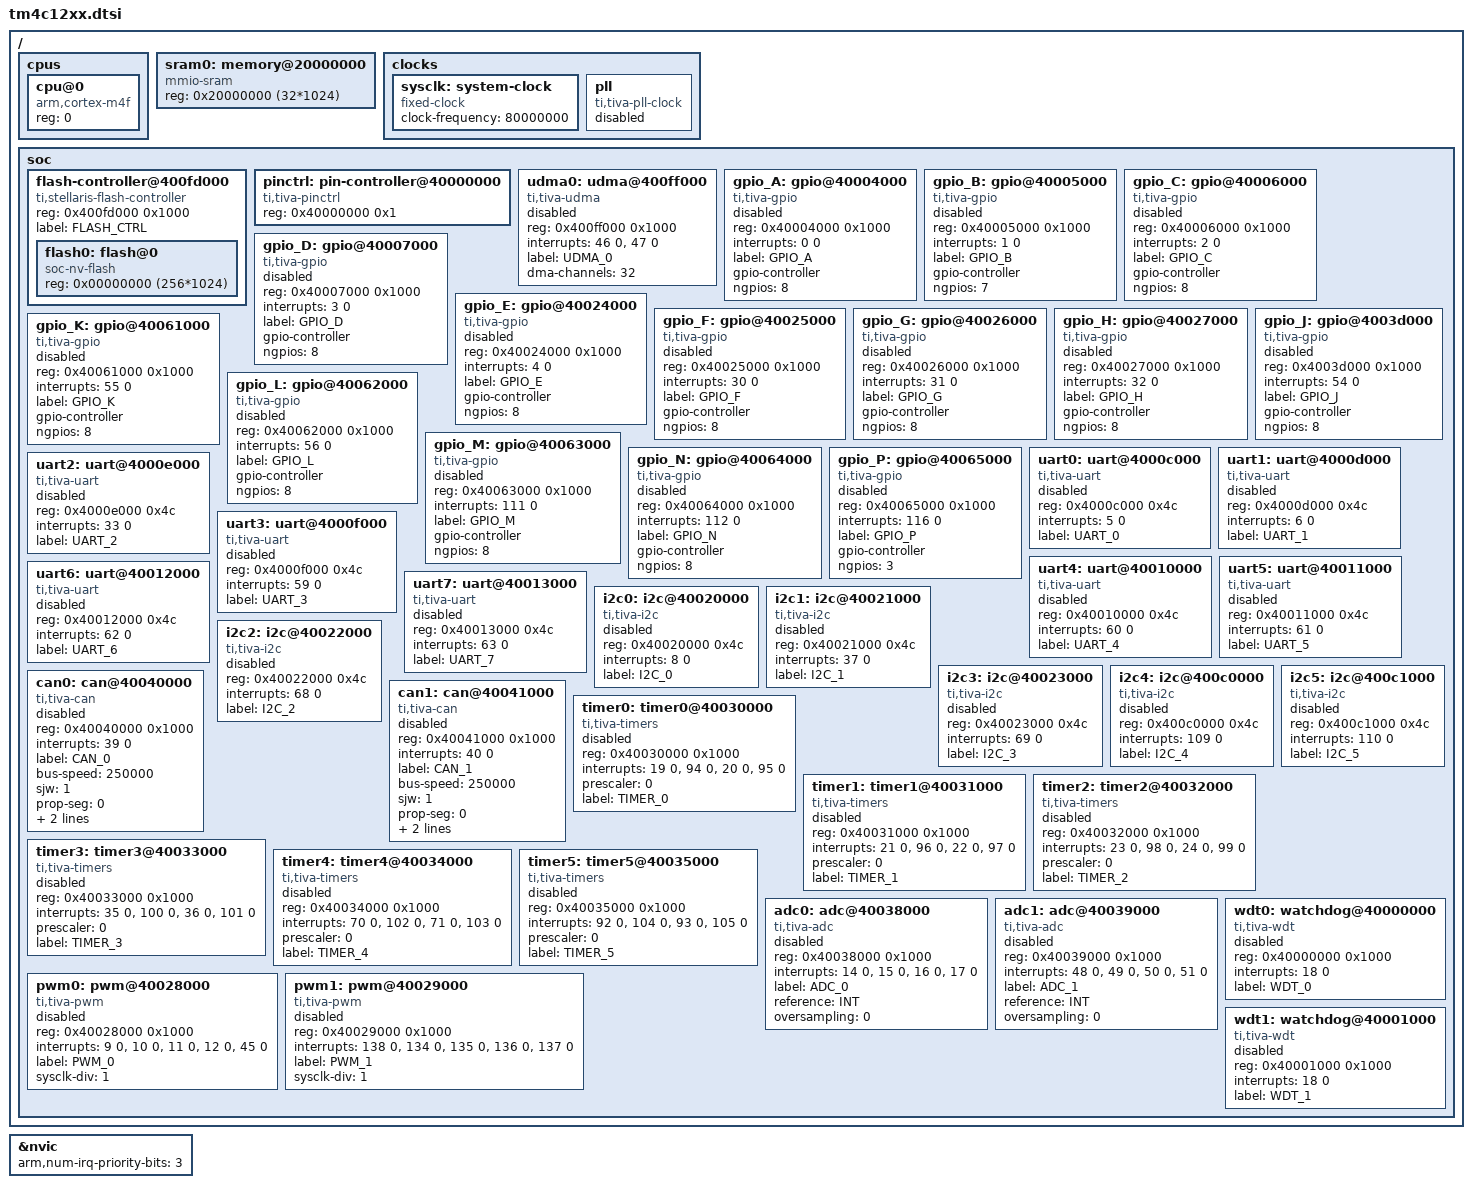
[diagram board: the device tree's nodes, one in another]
/*
 * Copyright (c) 2021 TIER SE
 *
 * SPDX-License-Identifier: Apache-2.0
 */

#include <arm/armv7-m.dtsi>
#include <dt-bindings/i2c/i2c.h>
#include <dt-bindings/gpio/gpio.h>

/ {
	cpus {
		#address-cells = <1>;
		#size-cells = <0>;

		cpu@0 {
			device_type = "cpu";
			compatible = "arm,cortex-m4f";
			reg = <0>;
		};
	};

	sram0: memory@20000000 {
		compatible = "mmio-sram";
		reg = <0x20000000 (32*1024)>;
	};

	clocks {
		sysclk: system-clock {
			compatible = "fixed-clock";
			clock-frequency = <80000000>;
			#clock-cells = <0>;
		};
		pll: pll {
			#clock-cells = <0>;
			compatible = "ti,tiva-pll-clock";
			status = "disabled";
		};
	};

	soc {

		flash-controller@400fd000 {
			compatible = "ti,stellaris-flash-controller";
			reg = <0x400fd000 0x1000>;
			#address-cells = <1>;
			#size-cells = <1>;
			label = "FLASH_CTRL";
			flash0: flash@0 {
				compatible = "soc-nv-flash";
				reg = <0x00000000 (256*1024)>;
			};
		};

		// fake pin controller with addr and register size
		pinctrl: pin-controller@40000000 {
			compatible = "ti,tiva-pinctrl";
			#address-cells = <1>;
			#size-cells = <1>;
			reg = <0x40000000 0x1>;
		};

		udma0: udma@400ff000 {
			compatible = "ti,tiva-udma";
			reg = <0x400ff000 0x1000>;
			interrupts = <46 0>, <47 0>;
			label = "UDMA_0";
			status = "disabled";
			dma-channels = <32>;
			#dma-cells = <2>;
		};

		gpio_A: gpio@40004000 {
			compatible = "ti,tiva-gpio";
			reg = <0x40004000 0x1000>;
			interrupts = <0 0>;
			label = "GPIO_A";
			gpio-controller;
			#gpio-cells = <2>;
			ngpios = <8>; // PA0-PA7
			status = "disabled";
		};

		gpio_B: gpio@40005000 {
			compatible = "ti,tiva-gpio";
			reg = <0x40005000 0x1000>;
			interrupts = <1 0>;
			label = "GPIO_B";
			gpio-controller;
			#gpio-cells = <2>;
			ngpios = <7>; // PB0-PB5
			status = "disabled";
		};

		gpio_C: gpio@40006000 {
			compatible = "ti,tiva-gpio";
			reg = <0x40006000 0x1000>;
			interrupts = <2 0>;
			label = "GPIO_C";
			gpio-controller;
			#gpio-cells = <2>;
			ngpios = <8>; // PC0-PC7
			status = "disabled";
		};

		gpio_D: gpio@40007000 {
			compatible = "ti,tiva-gpio";
			reg = <0x40007000 0x1000>;
			interrupts = <3 0>;
			label = "GPIO_D";
			gpio-controller;
			#gpio-cells = <2>;
			ngpios = <8>; // PD0-PD7
			status = "disabled";
		};

		gpio_E: gpio@40024000 {
			compatible = "ti,tiva-gpio";
			reg = <0x40024000 0x1000>;
			interrupts = <4 0>;
			label = "GPIO_E";
			gpio-controller;
			#gpio-cells = <2>;
			ngpios = <8>; // PE0-PE7
			status = "disabled";
		};

		gpio_F: gpio@40025000 {
			compatible = "ti,tiva-gpio";
			reg = <0x40025000 0x1000>;
			interrupts = <30 0>;
			label = "GPIO_F";
			gpio-controller;
			#gpio-cells = <2>;
			ngpios = <8>; // PF0-PF7
			status = "disabled";
		};

		gpio_G: gpio@40026000 {
			compatible = "ti,tiva-gpio";
			reg = <0x40026000 0x1000>;
			interrupts = <31 0>;
			label = "GPIO_G";
			gpio-controller;
			#gpio-cells = <2>;
			ngpios = <8>; // PG0-PG7
			status = "disabled";
		};

		gpio_H: gpio@40027000 {
			compatible = "ti,tiva-gpio";
			reg = <0x40027000 0x1000>;
			interrupts = <32 0>;
			label = "GPIO_H";
			gpio-controller;
			#gpio-cells = <2>;
			ngpios = <8>; // PH0-PH7
			status = "disabled";
		};

		gpio_J: gpio@4003d000 {
			compatible = "ti,tiva-gpio";
			reg = <0x4003d000 0x1000>;
			interrupts = <54 0>;
			label = "GPIO_J";
			gpio-controller;
			#gpio-cells = <2>;
			ngpios = <8>; // PJ0-PJ7
			status = "disabled";
		};

		gpio_K: gpio@40061000 {
			compatible = "ti,tiva-gpio";
			reg = <0x40061000 0x1000>;
			interrupts = <55 0>;
			label = "GPIO_K";
			gpio-controller;
			#gpio-cells = <2>;
			ngpios = <8>; // PK0-PK7
			status = "disabled";
		};

		gpio_L: gpio@40062000 {
			compatible = "ti,tiva-gpio";
			reg = <0x40062000 0x1000>;
			interrupts = <56 0>;
			label = "GPIO_L";
			gpio-controller;
			#gpio-cells = <2>;
			ngpios = <8>; // PL0-PL7
			status = "disabled";
		};

		gpio_M: gpio@40063000 {
			compatible = "ti,tiva-gpio";
			reg = <0x40063000 0x1000>;
			interrupts = <111 0>;
			label = "GPIO_M";
			gpio-controller;
			#gpio-cells = <2>;
			ngpios = <8>; // PM0-PM7
			status = "disabled";
		};

		gpio_N: gpio@40064000 {
			compatible = "ti,tiva-gpio";
			reg = <0x40064000 0x1000>;
			interrupts = <112 0>;
			label = "GPIO_N";
			gpio-controller;
			#gpio-cells = <2>;
			ngpios = <8>; // PN0-PN7
			status = "disabled";
		};

		gpio_P: gpio@40065000 {
			compatible = "ti,tiva-gpio";
			reg = <0x40065000 0x1000>;
			interrupts = <116 0>;
			label = "GPIO_P";
			gpio-controller;
			#gpio-cells = <2>;
			ngpios = <3>; // PP0-PP2
			status = "disabled";
		};

		uart0: uart@4000c000 {
			compatible = "ti,tiva-uart";
			reg = <0x4000c000 0x4c>;
			interrupts = <5 0>;
			status = "disabled";
			label = "UART_0";
		};

		uart1: uart@4000d000 {
			compatible = "ti,tiva-uart";
			reg = <0x4000d000 0x4c>;
			interrupts = <6 0>;
			status = "disabled";
			label = "UART_1";
		};

		uart2: uart@4000e000 {
			compatible = "ti,tiva-uart";
			reg = <0x4000e000 0x4c>;
			interrupts = <33 0>;
			status = "disabled";
			label = "UART_2";
		};

		uart3: uart@4000f000 {
			compatible = "ti,tiva-uart";
			reg = <0x4000f000 0x4c>;
			interrupts = <59 0>;
			status = "disabled";
			label = "UART_3";

		};

		uart4: uart@40010000 {
			compatible = "ti,tiva-uart";
			reg = <0x40010000 0x4c>;
			interrupts = <60 0>;
			status = "disabled";
			label = "UART_4";
		};

		uart5: uart@40011000 {
			compatible = "ti,tiva-uart";
			reg = <0x40011000 0x4c>;
			interrupts = <61 0>;
			status = "disabled";
			label = "UART_5";
		};

		uart6: uart@40012000 {
			compatible = "ti,tiva-uart";
			reg = <0x40012000 0x4c>;
			interrupts = <62 0>;
			status = "disabled";
			label = "UART_6";
		};

		uart7: uart@40013000 {
			compatible = "ti,tiva-uart";
			reg = <0x40013000 0x4c>;
			interrupts = <63 0>;
			status = "disabled";
			label = "UART_7";
		};

		i2c0: i2c@40020000 {
			compatible = "ti,tiva-i2c";
			reg = <0x40020000 0x4c>;
			#address-cells = <1>;
			#size-cells = <0>;
			interrupts = <8 0>;
			status = "disabled";
			label = "I2C_0";
		};

		i2c1: i2c@40021000 {
			compatible = "ti,tiva-i2c";
			reg = <0x40021000 0x4c>;
			#address-cells = <1>;
			#size-cells = <0>;
			interrupts = <37 0>;
			status = "disabled";
			label = "I2C_1";
		};

		i2c2: i2c@40022000 {
			compatible = "ti,tiva-i2c";
			reg = <0x40022000 0x4c>;
			#address-cells = <1>;
			#size-cells = <0>;
			interrupts = <68 0>;
			status = "disabled";
			label = "I2C_2";
		};

		i2c3: i2c@40023000 {
			compatible = "ti,tiva-i2c";
			reg = <0x40023000 0x4c>;
			#address-cells = <1>;
			#size-cells = <0>;
			interrupts = <69 0>;
			status = "disabled";
			label = "I2C_3";
		};

		i2c4: i2c@400c0000 {
			compatible = "ti,tiva-i2c";
			reg = <0x400c0000 0x4c>;
			#address-cells = <1>;
			#size-cells = <0>;
			interrupts = <109 0>;
			status = "disabled";
			label = "I2C_4";
		};

		i2c5: i2c@400c1000 {
			compatible = "ti,tiva-i2c";
			reg = <0x400c1000 0x4c>;
			#address-cells = <1>;
			#size-cells = <0>;
			interrupts = <110 0>;
			status = "disabled";
			label = "I2C_5";
		};

		can0: can@40040000 {
			compatible = "ti,tiva-can";
			#address-cells = <1>;
			#size-cells = <0>;
			reg = <0x40040000 0x1000>;
			interrupts = <39 0>;
			status = "disabled";
			label = "CAN_0";
			bus-speed = <250000>;
			sjw = <1>;
			prop-seg = <0>;
			phase-seg1 = <5>;
			phase-seg2 = <6>;
		};

		can1: can@40041000 {
			compatible = "ti,tiva-can";
			#address-cells = <1>;
			#size-cells = <0>;
			reg = <0x40041000 0x1000>;
			interrupts = <40 0>;
			status = "disabled";
			label = "CAN_1";
			bus-speed = <250000>;
			sjw = <1>;
			prop-seg = <0>;
			phase-seg1 = <5>;
			phase-seg2 = <6>;
		};

		timer0: timer0@40030000 {
			compatible = "ti,tiva-timers";
			reg = <0x40030000 0x1000>;
			interrupts = <19 0>, <94 0>, <20 0>, <95 0>;
			prescaler=<0>;
			label = "TIMER_0";
			status = "disabled";
		};

		timer1: timer1@40031000 {
			compatible = "ti,tiva-timers";
			reg = <0x40031000 0x1000>;
			interrupts = <21 0>, <96 0>, <22 0>, <97 0>;
			prescaler=<0>;
			label = "TIMER_1";
			status = "disabled";
		};

		timer2: timer2@40032000 {
			compatible = "ti,tiva-timers";
			reg = <0x40032000 0x1000>;
			interrupts = <23 0>, <98 0>, <24 0>, <99 0>;
			prescaler=<0>;
			label = "TIMER_2";
			status = "disabled";
		};

		timer3: timer3@40033000 {
			compatible = "ti,tiva-timers";
			reg = <0x40033000 0x1000>;
			interrupts = <35 0>, <100 0>, <36 0>, <101 0>;
			prescaler=<0>;
			label = "TIMER_3";
			status = "disabled";
		};

		timer4: timer4@40034000 {
			compatible = "ti,tiva-timers";
			reg = <0x40034000 0x1000>;
			interrupts = <70 0>, <102 0>, <71 0>, <103 0>;
			prescaler=<0>;
			label = "TIMER_4";
			status = "disabled";
		};

		timer5: timer5@40035000 {
			compatible = "ti,tiva-timers";
			reg = <0x40035000 0x1000>;
			interrupts = <92 0>, <104 0>, <93 0>, <105 0>;
			prescaler=<0>;
			label = "TIMER_5";
			status = "disabled";
		};


		adc0: adc@40038000 {
			compatible = "ti,tiva-adc";
			reg = <0x40038000 0x1000>;
			interrupts = <14 0>, <15 0>,<16 0>, <17 0>;
			label = "ADC_0";
			reference = "INT";
			oversampling = <0>;
			status = "disabled";
		};

		adc1: adc@40039000 {
			compatible = "ti,tiva-adc";
			reg = <0x40039000 0x1000>;
			interrupts = <48 0>, <49 0>, <50 0>, <51 0>;
			label = "ADC_1";
			reference = "INT";
			oversampling = <0>;
			status = "disabled";
		};

		pwm0: pwm@40028000 {
			compatible = "ti,tiva-pwm";
			reg = <0x40028000 0x1000>;
			// fault, gen0, gen1, gen2, gen3
			interrupts = <9 0>, <10 0>, <11 0>, <12 0>, <45 0>;
			label = "PWM_0";
			sysclk-div = <1>;
			status = "disabled";
		};

		pwm1: pwm@40029000 {
			compatible = "ti,tiva-pwm";
			reg = <0x40029000 0x1000>;
			// fault, gen0, gen1, gen2, gen3
			interrupts = <138 0>, <134 0>, <135 0>, <136 0>, <137 0>;
			label = "PWM_1";
			sysclk-div = <1>;
			status = "disabled";
		};

		wdt0: watchdog@40000000 {
			compatible = "ti,tiva-wdt";
			reg = <0x40000000 0x1000>;
			interrupts = <18 0>;
			label = "WDT_0";
			status = "disabled";
		};

		wdt1: watchdog@40001000 {
			compatible = "ti,tiva-wdt";
			reg = <0x40001000 0x1000>;
			interrupts = <18 0>;
			label = "WDT_1";
			status = "disabled";
		};

	};
};

&nvic {
	arm,num-irq-priority-bits=<3>;
};
